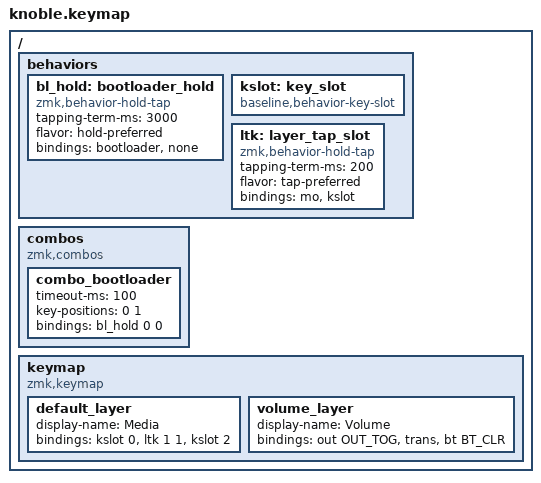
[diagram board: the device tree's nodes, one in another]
#include <behaviors.dtsi>
#include <dt-bindings/zmk/keys.h>
#include <dt-bindings/zmk/bt.h>
#include <dt-bindings/zmk/outputs.h>
#include <dt-bindings/zmk/ext_power.h>

/ {
    /* HOLD both keys for 3 seconds -> reboot into the UF2 bootloader
     * (NICENANO drive mounts; no physical double-tap needed).
     * Release early and nothing happens. */
    behaviors {
        bl_hold: bootloader_hold {
            compatible = "zmk,behavior-hold-tap";
            #binding-cells = <2>;
            tapping-term-ms = <3000>;
            flavor = "hold-preferred";
            bindings = <&bootloader>, <&none>;
        };

        /* Runtime-remappable key slots (companion app, raw-HID channel).
         * Defaults mirror the old &kp bindings: prev / play-pause / next. */
        kslot: key_slot {
            compatible = "baseline,behavior-key-slot";
            #binding-cells = <1>;
        };

        /* Like &lt but the tap keycode comes from a slot: hold = layer,
         * tap = &kslot <param2>. Same flavor/term as stock &lt. */
        ltk: layer_tap_slot {
            compatible = "zmk,behavior-hold-tap";
            #binding-cells = <2>;
            tapping-term-ms = <200>;
            flavor = "tap-preferred";
            bindings = <&mo>, <&kslot>;
        };
    };

    combos {
        compatible = "zmk,combos";
        combo_bootloader {
            timeout-ms = <100>;
            key-positions = <0 1>;
            bindings = <&bl_hold 0 0>;
        };
    };

    keymap {
        compatible = "zmk,keymap";

        /* Layer 0 — knob scrolls (profile_scroll).
         * Hold the middle key for layer 1. */
        default_layer {
            display-name = "Media";
            bindings = <&kslot 0  &ltk 1 1  &kslot 2>;
        };

        /* Layer 1 — knob is volume with finer detents (profile_volume).
         * Left key toggles USB/BLE output. Position 2 is unpopulated
         * on this PCB, so its binding is spare. */
        volume_layer {
            display-name = "Volume";
            bindings = <&out OUT_TOG  &trans  &bt BT_CLR>;
        };
    };
};
